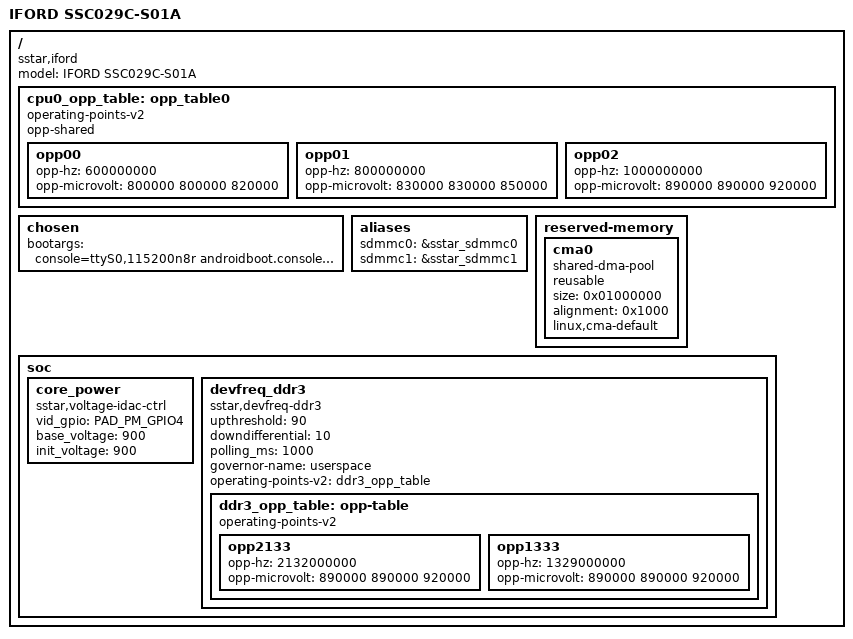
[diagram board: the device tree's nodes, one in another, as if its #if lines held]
/*
* iford-ssc029c-s01a-dualos.dts- Sigmastar
*
* Copyright (c) [2019~2020] SigmaStar Technology.
*
*
* This software is licensed under the terms of the GNU General Public
* License version 2, as published by the Free Software Foundation, and
* may be copied, distributed, and modified under those terms.
*
* This program is distributed in the hope that it will be useful,
* but WITHOUT ANY WARRANTY; without even the implied warranty of
* MERCHANTABILITY or FITNESS FOR A PARTICULAR PURPOSE.  See the
* GNU General Public License version 2 for more details.
*
*/

 /*
 * Memory Layout
 * 0x20000000-0x24000000 64M Kernel
 * 0x24000000-0x24800000 8M  system
 * 0x24800000-0x24900000 1M  data
 * 0x24900000-0x25000000 7M  temp0
 * 0x25000000-0x28000000 48M temp1
 */
/dts-v1/;

#include "iford.dtsi"
#include "iford-ssc029c-s01a-padmux.dtsi"

/ {
    #address-cells = <1>;
    #size-cells = <1>;
    model = "IFORD SSC029C-S01A";
    compatible = "sstar,iford";
/*
    memory {
        device_type = "memory";
        #address-cells = <2>;
        #size-cells = <2>;
        reg = <0x00000000 0x20000000 0x00000000 0x04000000>;
    };
*/
#if IS_ENABLED(CONFIG_SSTAR_VOLTAGE_IDAC_CTRL)
    cpu0_opp_table: opp_table0 {
        compatible = "operating-points-v2";
        opp-shared;

        opp00 {
            opp-hz = /bits/ 64 <600000000>;
            opp-microvolt = <800000 800000 820000>; /* <normal min max> */
            status = "ok";
        };

        opp01 {
            opp-hz = /bits/ 64 <800000000>;
            opp-microvolt = <830000 830000 850000>; /* <normal min max> */
            status = "ok";
        };

        opp02 {
            opp-hz = /bits/ 64 <1000000000>;
            opp-microvolt = <890000 890000 920000>;
            status = "ok";
        };
    };
#endif
    chosen {
        bootargs = "console=ttyS0,115200n8r androidboot.console=ttyS0 user_debug=31 root=/dev/mtdblock0 init=/linuxrc LX_MEM=0x1fee0000 mma_heap=mma_heap_name0,miu=0,sz=0xA000000,max_start_off=0x29800000 mma_memblock_remove=1 cma=2M nohz=off";
    };
#if IS_ENABLED(CONFIG_SSTAR_SDMMC)
    // mmc aliases
    aliases {
          sdmmc0 = &sstar_sdmmc0; //FCIE
          sdmmc1 = &sstar_sdmmc1; //SDIO
    };
#endif
/*!!IMPORTANT!! The reserved memory must be 1MB aligned*/
    reserved-memory {
        #address-cells = <1>;
        #size-cells = <1>;
        ranges;

        cma0 {
            compatible = "shared-dma-pool";
            reusable;
            size = <0x01000000>;
            alignment = <0x1000>;
            linux,cma-default;
        };
    };

#if IS_ENABLED(CONFIG_SSTAR_VOLTAGE_IDAC_CTRL) || IS_ENABLED(CONFIG_SSTAR_DDRFREQ)
    soc {
#if IS_ENABLED(CONFIG_SSTAR_VOLTAGE_IDAC_CTRL)
        core_power {
            compatible = "sstar,voltage-idac-ctrl";
            vid_gpio = <PAD_PM_GPIO4>;
            base_voltage = <900>;
            init_voltage = <900>;
            status = "ok";
        };
#endif

#if IS_ENABLED(CONFIG_SSTAR_DDRFREQ)
        devfreq_ddr3 {
            compatible = "sstar,devfreq-ddr3";
#if IS_ENABLED(CONFIG_DEVFREQ_GOV_SIMPLE_ONDEMAND)
            /* properties for simple_ondemand governor */
            upthreshold = <90>;
            downdifferential = <10>;
#endif
            polling_ms = <1000>;
            /* default governor */
            governor-name = "userspace"; /* available governor: "userspace", "simple_ondemand" */
            /* opp */
            operating-points-v2 = <&ddr3_opp_table>;
            status = "ok";

            ddr3_opp_table: opp-table {
                compatible = "operating-points-v2";
                opp2133 {
                    opp-hz = /bits/ 64 <2132000000>;
                    opp-microvolt = <890000 890000 920000>;
                    status = "ok";
                };
                opp1333 {
                    opp-hz = /bits/ 64 <1329000000>;
                    opp-microvolt = <890000 890000 920000>;
                    status = "ok";
                };
            };
        };
#endif
    };
#endif
};
